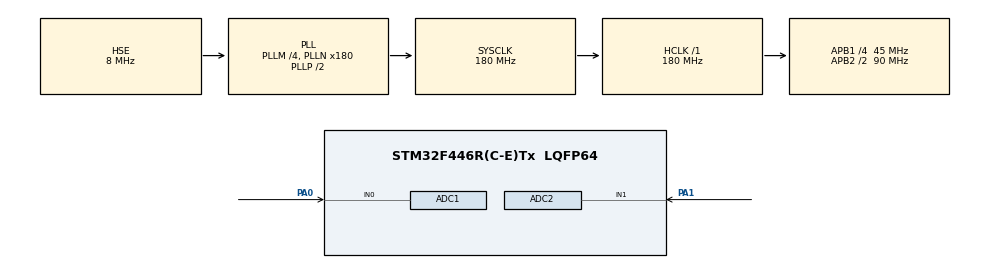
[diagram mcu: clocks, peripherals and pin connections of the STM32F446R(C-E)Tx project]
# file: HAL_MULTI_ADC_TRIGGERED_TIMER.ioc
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ADC1.Channel-1\#ChannelRegularConversion=ADC_CHANNEL_0
ADC1.ContinuousConvMode=DISABLE
ADC1.Mode=__NULL
ADC1.NbrOfConversion=1
ADC1.NbrOfConversionFlag=1
ADC1.Rank-1\#ChannelRegularConversion=1
ADC1.SamplingTime-1\#ChannelRegularConversion=ADC_SAMPLETIME_84CYCLES
ADC1.ScanConvMode=ENABLE
ADC1.master=1
ADC2.Channel-0\#ChannelRegularConversion=ADC_CHANNEL_1
ADC2.ContinuousConvMode=DISABLE
ADC2.NbrOfConversion=1
ADC2.NbrOfConversionFlag=1
ADC2.Rank-0\#ChannelRegularConversion=1
ADC2.SamplingTime-0\#ChannelRegularConversion=ADC_SAMPLETIME_84CYCLES
ADC2.ScanConvMode=ENABLE
Mcu.Family=STM32F4
Mcu.Name=STM32F446R(C-E)Tx
Mcu.Package=LQFP64
NVIC.ADC_IRQn=true\:0\:0\:false\:false\:true\:true\:true
NVIC.PriorityGroup=NVIC_PRIORITYGROUP_4
NVIC.TIM6_DAC_IRQn=true\:0\:0\:false\:false\:true\:true\:true
PA0-WKUP.Signal=ADCx_IN0
PA1.Signal=ADCx_IN1
PH0-OSC_IN.Mode=HSE-External-Oscillator
PH0-OSC_IN.Signal=RCC_OSC_IN
PH1-OSC_OUT.Mode=HSE-External-Oscillator
PH1-OSC_OUT.Signal=RCC_OSC_OUT
ProjectManager.HeapSize=0x200
ProjectManager.StackSize=0x400
ProjectManager.TargetToolchain=STM32CubeIDE
RCC.AHBFreq_Value=180000000
RCC.APB1CLKDivider=RCC_HCLK_DIV4
RCC.APB1Freq_Value=45000000
RCC.APB1TimFreq_Value=90000000
RCC.APB2CLKDivider=RCC_HCLK_DIV2
RCC.APB2Freq_Value=90000000
RCC.APB2TimFreq_Value=180000000
RCC.CortexFreq_Value=180000000
RCC.HCLKFreq_Value=180000000
RCC.HSE_VALUE=8000000
RCC.PLLM=4
RCC.PLLN=180
RCC.PLLSourceVirtual=RCC_PLLSOURCE_HSE
RCC.SYSCLKFreq_VALUE=180000000
RCC.SYSCLKSource=RCC_SYSCLKSOURCE_PLLCLK
RCC.USBFreq_Value=180000000
RCC.VCOOutputFreq_Value=360000000
SH.ADCx_IN0.0=ADC1_IN0,IN0
SH.ADCx_IN1.0=ADC2_IN1,IN1
TIM6.Period=11249
TIM6.TIM_MasterOutputTrigger=TIM_TRGO_UPDATE
VP_TIM6_VS_ClockSourceINT.Mode=Enable_Timer
board=custom

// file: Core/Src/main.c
/* USER CODE BEGIN Header */
/**
  ******************************************************************************
  * @file           : main.c
  * @brief          : Main program body
  ******************************************************************************
  * @attention
  *
  * <h2><center>&copy; Copyright (c) 2020 STMicroelectronics.
  * All rights reserved.</center></h2>
  *
  * This software component is licensed by ST under BSD 3-Clause license,
  * the "License"; You may not use this file except in compliance with the
  * License. You may obtain a copy of the License at:
  *                        opensource.org/licenses/BSD-3-Clause
  *
  ******************************************************************************
  */
/* USER CODE END Header */

#include "main.h"

ADC_HandleTypeDef hadc1;
ADC_HandleTypeDef hadc2;

TIM_HandleTypeDef htim6;

/* USER CODE BEGIN PV */

uint32_t data1 = 0 , data2 = 0 , i = 0;

/* USER CODE END PV */

void SystemClock_Config(void);
static void MX_GPIO_Init(void);
static void MX_ADC1_Init(void);
static void MX_ADC2_Init(void);
static void MX_TIM6_Init(void);

/* USER CODE BEGIN 0 */

/*****************		Interrupt Handler Functions		*****************/

void HAL_TIM_PeriodElapsedCallback(TIM_HandleTypeDef *htim)
{
	HAL_ADC_Start_IT(&hadc1);
	HAL_ADC_Start_IT(&hadc2);
}

void HAL_ADC_ConvCpltCallback(ADC_HandleTypeDef* hadc)
{
  if(ADC1->SR	&	(1<<1))
  {
	  data1=HAL_ADC_GetValue(&hadc1);
	  HAL_ADC_Stop_IT(&hadc1);

  }
  else if(ADC2->SR	&	(1<<1))
  {
	  data2=HAL_ADC_GetValue(&hadc2);
	  HAL_ADC_Stop_IT(&hadc2);
  }

}

/* USER CODE END 0 */

int main(void)
{

  /* MCU Configuration--------------------------------------------------------*/

  /* Reset of all peripherals, Initializes the Flash interface and the Systick. */
  HAL_Init();

  /* Configure the system clock */
  SystemClock_Config();

  /* Initialize all configured peripherals */
  MX_GPIO_Init();
  MX_ADC1_Init();
  MX_ADC2_Init();
  MX_TIM6_Init();
  /* USER CODE BEGIN 2 */
  HAL_TIM_Base_Start_IT(&htim6);

  /* USER CODE END 2 */

  /* Infinite loop */
  while (1)
  {

  }
}

void SystemClock_Config(void)
{
  RCC_OscInitTypeDef RCC_OscInitStruct = {0};
  RCC_ClkInitTypeDef RCC_ClkInitStruct = {0};

  /** Configure the main internal regulator output voltage
  */
  __HAL_RCC_PWR_CLK_ENABLE();
  __HAL_PWR_VOLTAGESCALING_CONFIG(PWR_REGULATOR_VOLTAGE_SCALE1);
  /** Initializes the CPU, AHB and APB busses clocks
  */
  RCC_OscInitStruct.OscillatorType = RCC_OSCILLATORTYPE_HSE;
  RCC_OscInitStruct.HSEState = RCC_HSE_ON;
  RCC_OscInitStruct.PLL.PLLState = RCC_PLL_ON;
  RCC_OscInitStruct.PLL.PLLSource = RCC_PLLSOURCE_HSE;
  RCC_OscInitStruct.PLL.PLLM = 4;
  RCC_OscInitStruct.PLL.PLLN = 180;
  RCC_OscInitStruct.PLL.PLLP = RCC_PLLP_DIV2;
  RCC_OscInitStruct.PLL.PLLQ = 2;
  RCC_OscInitStruct.PLL.PLLR = 2;
  if (HAL_RCC_OscConfig(&RCC_OscInitStruct) != HAL_OK)
  {
    Error_Handler();
  }
  /** Activate the Over-Drive mode
  */
  if (HAL_PWREx_EnableOverDrive() != HAL_OK)
  {
    Error_Handler();
  }
  /** Initializes the CPU, AHB and APB busses clocks
  */
  RCC_ClkInitStruct.ClockType = RCC_CLOCKTYPE_HCLK|RCC_CLOCKTYPE_SYSCLK
                              |RCC_CLOCKTYPE_PCLK1|RCC_CLOCKTYPE_PCLK2;
  RCC_ClkInitStruct.SYSCLKSource = RCC_SYSCLKSOURCE_PLLCLK;
  RCC_ClkInitStruct.AHBCLKDivider = RCC_SYSCLK_DIV1;
  RCC_ClkInitStruct.APB1CLKDivider = RCC_HCLK_DIV4;
  RCC_ClkInitStruct.APB2CLKDivider = RCC_HCLK_DIV2;

  if (HAL_RCC_ClockConfig(&RCC_ClkInitStruct, FLASH_LATENCY_5) != HAL_OK)
  {
    Error_Handler();
  }
}

static void MX_ADC1_Init(void)
{

  ADC_ChannelConfTypeDef sConfig = {0};

  /** Configure the global features of the ADC (Clock, Resolution, Data Alignment and number of conversion)
  */
  hadc1.Instance = ADC1;
  hadc1.Init.ClockPrescaler = ADC_CLOCK_SYNC_PCLK_DIV4;
  hadc1.Init.Resolution = ADC_RESOLUTION_12B;
  hadc1.Init.ScanConvMode = ENABLE;
  hadc1.Init.ContinuousConvMode = DISABLE;
  hadc1.Init.DiscontinuousConvMode = DISABLE;
  hadc1.Init.ExternalTrigConvEdge = ADC_EXTERNALTRIGCONVEDGE_NONE;
  hadc1.Init.ExternalTrigConv = ADC_SOFTWARE_START;
  hadc1.Init.DataAlign = ADC_DATAALIGN_RIGHT;
  hadc1.Init.NbrOfConversion = 1;
  hadc1.Init.DMAContinuousRequests = DISABLE;
  hadc1.Init.EOCSelection = ADC_EOC_SINGLE_CONV;
  if (HAL_ADC_Init(&hadc1) != HAL_OK)
  {
    Error_Handler();
  }
  /** Configure for the selected ADC regular channel its corresponding rank in the sequencer and its sample time.
  */
  sConfig.Channel = ADC_CHANNEL_0;
  sConfig.Rank = 1;
  sConfig.SamplingTime = ADC_SAMPLETIME_84CYCLES;
  if (HAL_ADC_ConfigChannel(&hadc1, &sConfig) != HAL_OK)
  {
    Error_Handler();
  }

}

static void MX_ADC2_Init(void)
{

  ADC_ChannelConfTypeDef sConfig = {0};

  /** Configure the global features of the ADC (Clock, Resolution, Data Alignment and number of conversion)
  */
  hadc2.Instance = ADC2;
  hadc2.Init.ClockPrescaler = ADC_CLOCK_SYNC_PCLK_DIV4;
  hadc2.Init.Resolution = ADC_RESOLUTION_12B;
  hadc2.Init.ScanConvMode = ENABLE;
  hadc2.Init.ContinuousConvMode = DISABLE;
  hadc2.Init.DiscontinuousConvMode = DISABLE;
  hadc2.Init.ExternalTrigConvEdge = ADC_EXTERNALTRIGCONVEDGE_NONE;
  hadc2.Init.ExternalTrigConv = ADC_SOFTWARE_START;
  hadc2.Init.DataAlign = ADC_DATAALIGN_RIGHT;
  hadc2.Init.NbrOfConversion = 1;
  hadc2.Init.DMAContinuousRequests = DISABLE;
  hadc2.Init.EOCSelection = ADC_EOC_SINGLE_CONV;
  if (HAL_ADC_Init(&hadc2) != HAL_OK)
  {
    Error_Handler();
  }
  /** Configure for the selected ADC regular channel its corresponding rank in the sequencer and its sample time.
  */
  sConfig.Channel = ADC_CHANNEL_1;
  sConfig.Rank = 1;
  sConfig.SamplingTime = ADC_SAMPLETIME_84CYCLES;
  if (HAL_ADC_ConfigChannel(&hadc2, &sConfig) != HAL_OK)
  {
    Error_Handler();
  }

}

static void MX_TIM6_Init(void)
{

  TIM_MasterConfigTypeDef sMasterConfig = {0};

  htim6.Instance = TIM6;
  htim6.Init.Prescaler = 0;
  htim6.Init.CounterMode = TIM_COUNTERMODE_UP;
  htim6.Init.Period = 11249;
  htim6.Init.AutoReloadPreload = TIM_AUTORELOAD_PRELOAD_DISABLE;
  if (HAL_TIM_Base_Init(&htim6) != HAL_OK)
  {
    Error_Handler();
  }
  sMasterConfig.MasterOutputTrigger = TIM_TRGO_UPDATE;
  sMasterConfig.MasterSlaveMode = TIM_MASTERSLAVEMODE_DISABLE;
  if (HAL_TIMEx_MasterConfigSynchronization(&htim6, &sMasterConfig) != HAL_OK)
  {
    Error_Handler();
  }

}

static void MX_GPIO_Init(void)
{

  /* GPIO Ports Clock Enable */
  __HAL_RCC_GPIOH_CLK_ENABLE();
  __HAL_RCC_GPIOA_CLK_ENABLE();

}

void Error_Handler(void)
{
}

/************************ (C) COPYRIGHT STMicroelectronics *****END OF FILE****/
